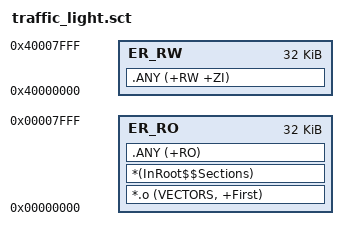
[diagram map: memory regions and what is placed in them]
LR_IROM1 0x00000000 0x00010000  ; 64 KB ROM at 0x00000000
{
    ER_RO 0x00000000 0x00008000  ; code + const data
    {
        *.o (VECTORS, +First)
        *(InRoot$$Sections)
        .ANY (+RO)
    }

    ER_RW 0x40000000 0x00008000  ; 32 KB RAM at 0x40000000
    {
        .ANY (+RW +ZI)
    }
}
